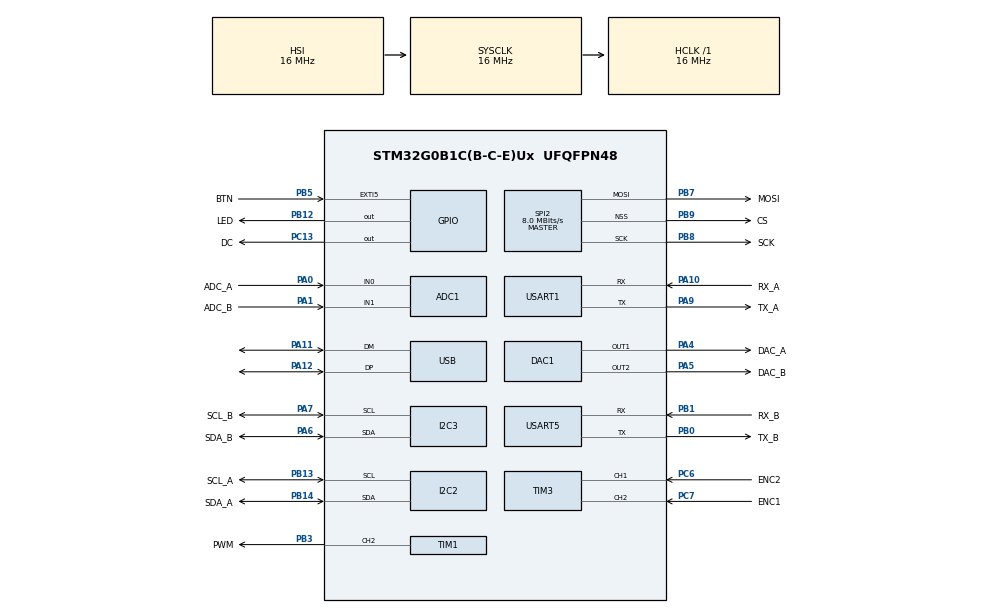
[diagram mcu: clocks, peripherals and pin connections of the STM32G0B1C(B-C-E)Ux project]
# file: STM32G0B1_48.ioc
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ADC1.ClockPrescaler=ADC_CLOCK_SYNC_PCLK_DIV2
ADC1.DMAContinuousRequests=ENABLE
ADC1.EOCSelection=ADC_EOC_SEQ_CONV
ADC1.ExternalTrigConv=ADC_EXTERNALTRIG_T6_TRGO
ADC1.NbrOfConversion=1
ADC1.NbrOfConversionFlag=0
ADC1.Overrun=ADC_OVR_DATA_PRESERVED
ADC1.OversamplingMode=ENABLE
ADC1.Ratio=ADC_OVERSAMPLING_RATIO_16
ADC1.RightBitShift=ADC_RIGHTBITSHIFT_4
ADC1.SamplingTimeCommon1=ADC_SAMPLETIME_160CYCLES_5
ADC1.SelectedChannel=ADC_CHANNEL_0|ADC_CHANNEL_1
ADC1.Sequencer=NOT_FULLY_CONFIGURABLE
ADC1.TriggerFrequencyMode=ADC_TRIGGER_FREQ_LOW
ADC1.master=1
DAC1.DAC_Channel-DAC_OUT1=DAC_CHANNEL_1
DAC1.DAC_Channel-DAC_OUT2=DAC_CHANNEL_2
Dma.ADC1.0.Direction=DMA_PERIPH_TO_MEMORY
Dma.ADC1.0.EventEnable=DISABLE
Dma.ADC1.0.Instance=DMA1_Channel1
Dma.ADC1.0.MemDataAlignment=DMA_MDATAALIGN_HALFWORD
Dma.ADC1.0.MemInc=DMA_MINC_ENABLE
Dma.ADC1.0.Mode=DMA_CIRCULAR
Dma.ADC1.0.PeriphDataAlignment=DMA_PDATAALIGN_HALFWORD
Dma.ADC1.0.PeriphInc=DMA_PINC_DISABLE
Dma.ADC1.0.Polarity=HAL_DMAMUX_REQ_GEN_RISING
Dma.ADC1.0.Priority=DMA_PRIORITY_LOW
Dma.ADC1.0.RequestNumber=1
Dma.ADC1.0.SignalID=NONE
Dma.ADC1.0.SyncEnable=DISABLE
Dma.ADC1.0.SyncPolarity=HAL_DMAMUX_SYNC_NO_EVENT
Dma.ADC1.0.SyncRequestNumber=1
Dma.ADC1.0.SyncSignalID=NONE
Dma.Request0=ADC1
I2C2.CustomTiming=Enabled
I2C2.I2C_Fall_Time=100
I2C2.I2C_Rise_Time=400
I2C2.Timing=0x306A0F13
I2C3.I2C_Fall_Time=100
I2C3.I2C_Rise_Time=400
I2C3.Timing=0x00A03D53
Mcu.Family=STM32G0
Mcu.Name=STM32G0B1C(B-C-E)Ux
Mcu.Package=UFQFPN48
Mcu.UserConstants=TIMERS_CLOCK_FREQ,16000000
NVIC.ADC1_COMP_IRQn=true\:1\:0\:true\:false\:true\:true\:true\:true
NVIC.DMA1_Channel1_IRQn=true\:0\:0\:false\:false\:true\:false\:true\:true
NVIC.EXTI4_15_IRQn=true\:0\:0\:false\:false\:true\:true\:true\:true
NVIC.TIM3_TIM4_IRQn=true\:0\:0\:false\:false\:true\:true\:true\:true
NVIC.TIM6_DAC_LPTIM1_IRQn=true\:0\:0\:false\:false\:true\:true\:true\:true
PA0.GPIO_Label=ADC_A
PA0.Mode=IN0
PA0.Signal=ADC1_IN0
PA1.GPIO_Label=ADC_B
PA1.Mode=IN1
PA1.Signal=ADC1_IN1
PA10.GPIO_Label=RX_A
PA10.Mode=Asynchronous
PA10.Signal=USART1_RX
PA11\ [PA9].Mode=Device
PA11\ [PA9].Signal=USB_DM
PA12\ [PA10].Mode=Device
PA12\ [PA10].Signal=USB_DP
PA13.GPIO_Label=SWDIO
PA13.Mode=Serial_Wire
PA13.Signal=SYS_SWDIO
PA14-BOOT0.GPIO_Label=SWCLK
PA14-BOOT0.Mode=Serial_Wire
PA14-BOOT0.Signal=SYS_SWCLK
PA4.GPIO_Label=DAC_A
PA4.Signal=COMP_DAC11_group
PA5.GPIO_Label=DAC_B
PA5.Signal=COMP_DAC12_group
PA6.GPIO_Label=SDA_B
PA6.Mode=I2C
PA6.Signal=I2C3_SDA
PA7.GPIO_Label=SCL_B
PA7.Mode=I2C
PA7.Signal=I2C3_SCL
PA9.GPIO_Label=TX_A
PA9.Mode=Asynchronous
PA9.Signal=USART1_TX
PB0.GPIO_Label=TX_B
PB0.Mode=Asynchronous
PB0.Signal=USART5_TX
PB1.GPIO_Label=RX_B
PB1.Mode=Asynchronous
PB1.Signal=USART5_RX
PB12.GPIO_Label=LED
PB12.GPIO_ModeDefaultOutputPP=GPIO_MODE_OUTPUT_PP
PB12.GPIO_PuPd=GPIO_NOPULL
PB12.Signal=GPIO_Output
PB13.GPIO_Label=SCL_A
PB13.Mode=I2C
PB13.Signal=I2C2_SCL
PB14.GPIO_Label=SDA_A
PB14.Mode=I2C
PB14.Signal=I2C2_SDA
PB3.GPIO_Label=PWM
PB3.Signal=S_TIM1_CH2
PB5.GPIO_Label=BTN
PB5.Signal=GPXTI5
PB7.GPIO_Label=MOSI
PB7.Mode=TX_Only_Simplex_Unidirect_Master
PB7.Signal=SPI2_MOSI
PB8.GPIO_Label=SCK
PB8.Mode=TX_Only_Simplex_Unidirect_Master
PB8.Signal=SPI2_SCK
PB9.GPIO_Label=CS
PB9.Mode=NSS_Signal_Hard_Output
PB9.Signal=SPI2_NSS
PC13.GPIO_Label=DC
PC13.Signal=GPIO_Output
PC6.GPIO_Label=ENC2
PC6.Signal=S_TIM3_CH1
PC7.GPIO_Label=ENC1
PC7.Signal=S_TIM3_CH2
ProjectManager.HeapSize=0x200
ProjectManager.StackSize=0x400
ProjectManager.TargetToolchain=STM32CubeIDE
RCC.ADCCLockSelection=RCC_ADCCLKSOURCE_HSI
RCC.ADCFreq_Value=16000000
RCC.AHBFreq_Value=16000000
RCC.CortexFreq_Value=16000000
RCC.EXTERNAL_CLOCK_VALUE=48000
RCC.HCLKFreq_Value=16000000
RCC.HSE_VALUE=8000000
RCC.HSI48_VALUE=48000000
RCC.HSI_VALUE=16000000
RCC.I2C2CLockSelection=RCC_I2C2CLKSOURCE_SYSCLK
RCC.LSE_VALUE=32768
RCC.SYSCLKFreq_VALUE=16000000
RCC.USBFreq_Value=48000000
RCC.VCOOutputFreq_Value=128000000
SH.COMP_DAC11_group.0=DAC1_OUT1,DAC_OUT1
SH.COMP_DAC12_group.0=DAC1_OUT2,DAC_OUT2
SH.S_TIM1_CH2.0=TIM1_CH2,PWM Generation2 CH2
SH.S_TIM3_CH1.0=TIM3_CH1,Encoder_Interface
SH.S_TIM3_CH2.0=TIM3_CH2,Encoder_Interface
SPI2.CalculateBaudRate=8.0 MBits/s
SPI2.Direction=SPI_DIRECTION_2LINES
SPI2.Mode=SPI_MODE_MASTER
SPI2.VirtualNSS=VM_NSSHARD
SPI2.VirtualType=VM_MASTER
TIM1.Channel-PWM\ Generation2\ CH2=TIM_CHANNEL_2
TIM1.Period=(TIMERS_CLOCK_FREQ/1000)-1
TIM3.IC1Filter=10
TIM3.IC2Filter=10
TIM6.Period=250-1
TIM6.Prescaler=(TIMERS_CLOCK_FREQ/1000)-1
TIM6.TIM_MasterOutputTrigger=TIM_TRGO_UPDATE
USART1.VirtualMode-Asynchronous=VM_ASYNC
USART5.VirtualMode-Asynchronous=VM_ASYNC
VP_SYS_VS_DBSignals.Mode=DisableDeadBatterySignals
VP_SYS_V_VREFBUF.Mode=ExternalMode
VP_TIM1_VS_ClockSourceINT.Mode=Internal
VP_TIM6_VS_ClockSourceINT.Mode=Enable_Timer
board=custom

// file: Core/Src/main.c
/* USER CODE BEGIN Header */
/**
  ******************************************************************************
  * @file           : main.c
  * @brief          : Main program body
  ******************************************************************************
  * @attention
  *
  * Copyright (c) 2021 STMicroelectronics.
  * All rights reserved.
  *
  * This software is licensed under terms that can be found in the LICENSE file
  * in the root directory of this software component.
  * If no LICENSE file comes with this software, it is provided AS-IS.
  *
  ******************************************************************************
  */
/* USER CODE END Header */
#include "main.h"

/* USER CODE BEGIN Includes */
#include "master.h"
/* USER CODE END Includes */

/* USER CODE BEGIN PM */
// ?
/* USER CODE END PM */

ADC_HandleTypeDef hadc1;
DMA_HandleTypeDef hdma_adc1;

DAC_HandleTypeDef hdac1;

I2C_HandleTypeDef hi2c2;
I2C_HandleTypeDef hi2c3;

SPI_HandleTypeDef hspi2;

TIM_HandleTypeDef htim1;
TIM_HandleTypeDef htim3;
TIM_HandleTypeDef htim6;

UART_HandleTypeDef huart1;
UART_HandleTypeDef huart5;

PCD_HandleTypeDef hpcd_USB_DRD_FS;

void SystemClock_Config(void);
static void MX_GPIO_Init(void);
static void MX_DMA_Init(void);
static void MX_I2C2_Init(void);
static void MX_I2C3_Init(void);
static void MX_SPI2_Init(void);
static void MX_TIM1_Init(void);
static void MX_TIM3_Init(void);
static void MX_TIM6_Init(void);
static void MX_ADC1_Init(void);
static void MX_DAC1_Init(void);
static void MX_USART1_UART_Init(void);
static void MX_USART5_UART_Init(void);
static void MX_USB_DRD_FS_PCD_Init(void);

int main(void)
{
  /* USER CODE BEGIN 1 */
 PreInit();
  /* USER CODE END 1 */

  /* MCU Configuration--------------------------------------------------------*/

  /* Reset of all peripherals, Initializes the Flash interface and the Systick. */
  HAL_Init();

  /* USER CODE BEGIN Init */
  Init();
  /* USER CODE END Init */

  /* Configure the system clock */
  SystemClock_Config();

  /* USER CODE BEGIN SysInit */
  SysInit();
  /* USER CODE END SysInit */

  /* Initialize all configured peripherals */
  MX_GPIO_Init();
  MX_DMA_Init();
  MX_I2C2_Init();
  MX_I2C3_Init();
  MX_SPI2_Init();
  MX_TIM1_Init();
  MX_TIM3_Init();
  MX_TIM6_Init();
  MX_ADC1_Init();
  MX_DAC1_Init();
  MX_USART1_UART_Init();
  MX_USART5_UART_Init();
  MX_USB_DRD_FS_PCD_Init();
  /* USER CODE BEGIN 2 */
  PostInit();
  /* USER CODE END 2 */

  /* Infinite loop */
  while (1)
  {

    /* USER CODE BEGIN 3 */
    MainLoop();
  }
  /* USER CODE END 3 */
}

void SystemClock_Config(void)
{
  RCC_OscInitTypeDef RCC_OscInitStruct = {0};
  RCC_ClkInitTypeDef RCC_ClkInitStruct = {0};

  /** Configure the main internal regulator output voltage
  */
  HAL_PWREx_ControlVoltageScaling(PWR_REGULATOR_VOLTAGE_SCALE1);
  /** Initializes the RCC Oscillators according to the specified parameters
  * in the RCC_OscInitTypeDef structure.
  */
  RCC_OscInitStruct.OscillatorType = RCC_OSCILLATORTYPE_HSI|RCC_OSCILLATORTYPE_HSI48;
  RCC_OscInitStruct.HSIState = RCC_HSI_ON;
  RCC_OscInitStruct.HSI48State = RCC_HSI48_ON;
  RCC_OscInitStruct.HSIDiv = RCC_HSI_DIV1;
  RCC_OscInitStruct.HSICalibrationValue = RCC_HSICALIBRATION_DEFAULT;
  RCC_OscInitStruct.PLL.PLLState = RCC_PLL_NONE;
  if (HAL_RCC_OscConfig(&RCC_OscInitStruct) != HAL_OK)
  {
    Error_Handler();
  }
  /** Initializes the CPU, AHB and APB buses clocks
  */
  RCC_ClkInitStruct.ClockType = RCC_CLOCKTYPE_HCLK|RCC_CLOCKTYPE_SYSCLK
                              |RCC_CLOCKTYPE_PCLK1;
  RCC_ClkInitStruct.SYSCLKSource = RCC_SYSCLKSOURCE_HSI;
  RCC_ClkInitStruct.AHBCLKDivider = RCC_SYSCLK_DIV1;
  RCC_ClkInitStruct.APB1CLKDivider = RCC_HCLK_DIV1;

  if (HAL_RCC_ClockConfig(&RCC_ClkInitStruct, FLASH_LATENCY_0) != HAL_OK)
  {
    Error_Handler();
  }
}

static void MX_ADC1_Init(void)
{

  ADC_ChannelConfTypeDef sConfig = {0};

  /** Configure the global features of the ADC (Clock, Resolution, Data Alignment and number of conversion)
  */
  hadc1.Instance = ADC1;
  hadc1.Init.ClockPrescaler = ADC_CLOCK_SYNC_PCLK_DIV2;
  hadc1.Init.Resolution = ADC_RESOLUTION_12B;
  hadc1.Init.DataAlign = ADC_DATAALIGN_RIGHT;
  hadc1.Init.ScanConvMode = ADC_SCAN_SEQ_FIXED;
  hadc1.Init.EOCSelection = ADC_EOC_SEQ_CONV;
  hadc1.Init.LowPowerAutoWait = DISABLE;
  hadc1.Init.LowPowerAutoPowerOff = DISABLE;
  hadc1.Init.ContinuousConvMode = DISABLE;
  hadc1.Init.NbrOfConversion = 1;
  hadc1.Init.DiscontinuousConvMode = DISABLE;
  hadc1.Init.ExternalTrigConv = ADC_EXTERNALTRIG_T6_TRGO;
  hadc1.Init.ExternalTrigConvEdge = ADC_EXTERNALTRIGCONVEDGE_RISING;
  hadc1.Init.DMAContinuousRequests = ENABLE;
  hadc1.Init.Overrun = ADC_OVR_DATA_PRESERVED;
  hadc1.Init.SamplingTimeCommon1 = ADC_SAMPLETIME_160CYCLES_5;
  hadc1.Init.OversamplingMode = ENABLE;
  hadc1.Init.Oversampling.Ratio = ADC_OVERSAMPLING_RATIO_16;
  hadc1.Init.Oversampling.RightBitShift = ADC_RIGHTBITSHIFT_4;
  hadc1.Init.Oversampling.TriggeredMode = ADC_TRIGGEREDMODE_SINGLE_TRIGGER;
  hadc1.Init.TriggerFrequencyMode = ADC_TRIGGER_FREQ_LOW;
  if (HAL_ADC_Init(&hadc1) != HAL_OK)
  {
    Error_Handler();
  }
  /** Configure Regular Channel
  */
  sConfig.Channel = ADC_CHANNEL_0;
  sConfig.Rank = ADC_RANK_CHANNEL_NUMBER;
  if (HAL_ADC_ConfigChannel(&hadc1, &sConfig) != HAL_OK)
  {
    Error_Handler();
  }
  /** Configure Regular Channel
  */
  sConfig.Channel = ADC_CHANNEL_1;
  if (HAL_ADC_ConfigChannel(&hadc1, &sConfig) != HAL_OK)
  {
    Error_Handler();
  }

}

static void MX_DAC1_Init(void)
{

  DAC_ChannelConfTypeDef sConfig = {0};

  /** DAC Initialization
  */
  hdac1.Instance = DAC1;
  if (HAL_DAC_Init(&hdac1) != HAL_OK)
  {
    Error_Handler();
  }
  /** DAC channel OUT1 config
  */
  sConfig.DAC_SampleAndHold = DAC_SAMPLEANDHOLD_DISABLE;
  sConfig.DAC_Trigger = DAC_TRIGGER_NONE;
  sConfig.DAC_OutputBuffer = DAC_OUTPUTBUFFER_ENABLE;
  sConfig.DAC_ConnectOnChipPeripheral = DAC_CHIPCONNECT_DISABLE;
  sConfig.DAC_UserTrimming = DAC_TRIMMING_FACTORY;
  if (HAL_DAC_ConfigChannel(&hdac1, &sConfig, DAC_CHANNEL_1) != HAL_OK)
  {
    Error_Handler();
  }
  /** DAC channel OUT2 config
  */
  if (HAL_DAC_ConfigChannel(&hdac1, &sConfig, DAC_CHANNEL_2) != HAL_OK)
  {
    Error_Handler();
  }

}

static void MX_I2C2_Init(void)
{

  hi2c2.Instance = I2C2;
  hi2c2.Init.Timing = 0x306A0F13;
  hi2c2.Init.OwnAddress1 = 0;
  hi2c2.Init.AddressingMode = I2C_ADDRESSINGMODE_7BIT;
  hi2c2.Init.DualAddressMode = I2C_DUALADDRESS_DISABLE;
  hi2c2.Init.OwnAddress2 = 0;
  hi2c2.Init.OwnAddress2Masks = I2C_OA2_NOMASK;
  hi2c2.Init.GeneralCallMode = I2C_GENERALCALL_DISABLE;
  hi2c2.Init.NoStretchMode = I2C_NOSTRETCH_DISABLE;
  if (HAL_I2C_Init(&hi2c2) != HAL_OK)
  {
    Error_Handler();
  }
  /** Configure Analogue filter
  */
  if (HAL_I2CEx_ConfigAnalogFilter(&hi2c2, I2C_ANALOGFILTER_ENABLE) != HAL_OK)
  {
    Error_Handler();
  }
  /** Configure Digital filter
  */
  if (HAL_I2CEx_ConfigDigitalFilter(&hi2c2, 0) != HAL_OK)
  {
    Error_Handler();
  }

}

static void MX_I2C3_Init(void)
{

  hi2c3.Instance = I2C3;
  hi2c3.Init.Timing = 0x00A03D53;
  hi2c3.Init.OwnAddress1 = 0;
  hi2c3.Init.AddressingMode = I2C_ADDRESSINGMODE_7BIT;
  hi2c3.Init.DualAddressMode = I2C_DUALADDRESS_DISABLE;
  hi2c3.Init.OwnAddress2 = 0;
  hi2c3.Init.OwnAddress2Masks = I2C_OA2_NOMASK;
  hi2c3.Init.GeneralCallMode = I2C_GENERALCALL_DISABLE;
  hi2c3.Init.NoStretchMode = I2C_NOSTRETCH_DISABLE;
  if (HAL_I2C_Init(&hi2c3) != HAL_OK)
  {
    Error_Handler();
  }
  /** Configure Analogue filter
  */
  if (HAL_I2CEx_ConfigAnalogFilter(&hi2c3, I2C_ANALOGFILTER_ENABLE) != HAL_OK)
  {
    Error_Handler();
  }
  /** Configure Digital filter
  */
  if (HAL_I2CEx_ConfigDigitalFilter(&hi2c3, 0) != HAL_OK)
  {
    Error_Handler();
  }

}

static void MX_SPI2_Init(void)
{

  /* SPI2 parameter configuration*/
  hspi2.Instance = SPI2;
  hspi2.Init.Mode = SPI_MODE_MASTER;
  hspi2.Init.Direction = SPI_DIRECTION_2LINES;
  hspi2.Init.DataSize = SPI_DATASIZE_8BIT;
  hspi2.Init.CLKPolarity = SPI_POLARITY_LOW;
  hspi2.Init.CLKPhase = SPI_PHASE_1EDGE;
  hspi2.Init.NSS = SPI_NSS_HARD_OUTPUT;
  hspi2.Init.BaudRatePrescaler = SPI_BAUDRATEPRESCALER_2;
  hspi2.Init.FirstBit = SPI_FIRSTBIT_MSB;
  hspi2.Init.TIMode = SPI_TIMODE_DISABLE;
  hspi2.Init.CRCCalculation = SPI_CRCCALCULATION_DISABLE;
  hspi2.Init.CRCPolynomial = 7;
  hspi2.Init.CRCLength = SPI_CRC_LENGTH_DATASIZE;
  hspi2.Init.NSSPMode = SPI_NSS_PULSE_ENABLE;
  if (HAL_SPI_Init(&hspi2) != HAL_OK)
  {
    Error_Handler();
  }

}

static void MX_TIM1_Init(void)
{

  TIM_ClockConfigTypeDef sClockSourceConfig = {0};
  TIM_MasterConfigTypeDef sMasterConfig = {0};
  TIM_OC_InitTypeDef sConfigOC = {0};
  TIM_BreakDeadTimeConfigTypeDef sBreakDeadTimeConfig = {0};

  htim1.Instance = TIM1;
  htim1.Init.Prescaler = 0;
  htim1.Init.CounterMode = TIM_COUNTERMODE_UP;
  htim1.Init.Period = (TIMERS_CLOCK_FREQ/1000)-1;
  htim1.Init.ClockDivision = TIM_CLOCKDIVISION_DIV1;
  htim1.Init.RepetitionCounter = 0;
  htim1.Init.AutoReloadPreload = TIM_AUTORELOAD_PRELOAD_DISABLE;
  if (HAL_TIM_Base_Init(&htim1) != HAL_OK)
  {
    Error_Handler();
  }
  sClockSourceConfig.ClockSource = TIM_CLOCKSOURCE_INTERNAL;
  if (HAL_TIM_ConfigClockSource(&htim1, &sClockSourceConfig) != HAL_OK)
  {
    Error_Handler();
  }
  if (HAL_TIM_PWM_Init(&htim1) != HAL_OK)
  {
    Error_Handler();
  }
  sMasterConfig.MasterOutputTrigger = TIM_TRGO_RESET;
  sMasterConfig.MasterOutputTrigger2 = TIM_TRGO2_RESET;
  sMasterConfig.MasterSlaveMode = TIM_MASTERSLAVEMODE_DISABLE;
  if (HAL_TIMEx_MasterConfigSynchronization(&htim1, &sMasterConfig) != HAL_OK)
  {
    Error_Handler();
  }
  sConfigOC.OCMode = TIM_OCMODE_PWM1;
  sConfigOC.Pulse = 0;
  sConfigOC.OCPolarity = TIM_OCPOLARITY_HIGH;
  sConfigOC.OCNPolarity = TIM_OCNPOLARITY_HIGH;
  sConfigOC.OCFastMode = TIM_OCFAST_DISABLE;
  sConfigOC.OCIdleState = TIM_OCIDLESTATE_RESET;
  sConfigOC.OCNIdleState = TIM_OCNIDLESTATE_RESET;
  if (HAL_TIM_PWM_ConfigChannel(&htim1, &sConfigOC, TIM_CHANNEL_2) != HAL_OK)
  {
    Error_Handler();
  }
  sBreakDeadTimeConfig.OffStateRunMode = TIM_OSSR_DISABLE;
  sBreakDeadTimeConfig.OffStateIDLEMode = TIM_OSSI_DISABLE;
  sBreakDeadTimeConfig.LockLevel = TIM_LOCKLEVEL_OFF;
  sBreakDeadTimeConfig.DeadTime = 0;
  sBreakDeadTimeConfig.BreakState = TIM_BREAK_DISABLE;
  sBreakDeadTimeConfig.BreakPolarity = TIM_BREAKPOLARITY_HIGH;
  sBreakDeadTimeConfig.BreakFilter = 0;
  sBreakDeadTimeConfig.BreakAFMode = TIM_BREAK_AFMODE_INPUT;
  sBreakDeadTimeConfig.Break2State = TIM_BREAK2_DISABLE;
  sBreakDeadTimeConfig.Break2Polarity = TIM_BREAK2POLARITY_HIGH;
  sBreakDeadTimeConfig.Break2Filter = 0;
  sBreakDeadTimeConfig.Break2AFMode = TIM_BREAK_AFMODE_INPUT;
  sBreakDeadTimeConfig.AutomaticOutput = TIM_AUTOMATICOUTPUT_DISABLE;
  if (HAL_TIMEx_ConfigBreakDeadTime(&htim1, &sBreakDeadTimeConfig) != HAL_OK)
  {
    Error_Handler();
  }
  HAL_TIM_MspPostInit(&htim1);

}

static void MX_TIM3_Init(void)
{

  TIM_Encoder_InitTypeDef sConfig = {0};
  TIM_MasterConfigTypeDef sMasterConfig = {0};

  htim3.Instance = TIM3;
  htim3.Init.Prescaler = 0;
  htim3.Init.CounterMode = TIM_COUNTERMODE_UP;
  htim3.Init.Period = 65535;
  htim3.Init.ClockDivision = TIM_CLOCKDIVISION_DIV1;
  htim3.Init.AutoReloadPreload = TIM_AUTORELOAD_PRELOAD_DISABLE;
  sConfig.EncoderMode = TIM_ENCODERMODE_TI1;
  sConfig.IC1Polarity = TIM_ICPOLARITY_RISING;
  sConfig.IC1Selection = TIM_ICSELECTION_DIRECTTI;
  sConfig.IC1Prescaler = TIM_ICPSC_DIV1;
  sConfig.IC1Filter = 10;
  sConfig.IC2Polarity = TIM_ICPOLARITY_RISING;
  sConfig.IC2Selection = TIM_ICSELECTION_DIRECTTI;
  sConfig.IC2Prescaler = TIM_ICPSC_DIV1;
  sConfig.IC2Filter = 10;
  if (HAL_TIM_Encoder_Init(&htim3, &sConfig) != HAL_OK)
  {
    Error_Handler();
  }
  sMasterConfig.MasterOutputTrigger = TIM_TRGO_RESET;
  sMasterConfig.MasterSlaveMode = TIM_MASTERSLAVEMODE_DISABLE;
  if (HAL_TIMEx_MasterConfigSynchronization(&htim3, &sMasterConfig) != HAL_OK)
  {
    Error_Handler();
  }

}

static void MX_TIM6_Init(void)
{

  TIM_MasterConfigTypeDef sMasterConfig = {0};

  htim6.Instance = TIM6;
  htim6.Init.Prescaler = (TIMERS_CLOCK_FREQ/1000)-1;
  htim6.Init.CounterMode = TIM_COUNTERMODE_UP;
  htim6.Init.Period = 250-1;
  htim6.Init.AutoReloadPreload = TIM_AUTORELOAD_PRELOAD_DISABLE;
  if (HAL_TIM_Base_Init(&htim6) != HAL_OK)
  {
    Error_Handler();
  }
  sMasterConfig.MasterOutputTrigger = TIM_TRGO_UPDATE;
  sMasterConfig.MasterSlaveMode = TIM_MASTERSLAVEMODE_DISABLE;
  if (HAL_TIMEx_MasterConfigSynchronization(&htim6, &sMasterConfig) != HAL_OK)
  {
    Error_Handler();
  }

}

static void MX_USART1_UART_Init(void)
{

  huart1.Instance = USART1;
  huart1.Init.BaudRate = 115200;
  huart1.Init.WordLength = UART_WORDLENGTH_8B;
  huart1.Init.StopBits = UART_STOPBITS_1;
  huart1.Init.Parity = UART_PARITY_NONE;
  huart1.Init.Mode = UART_MODE_TX_RX;
  huart1.Init.HwFlowCtl = UART_HWCONTROL_NONE;
  huart1.Init.OverSampling = UART_OVERSAMPLING_16;
  huart1.Init.OneBitSampling = UART_ONE_BIT_SAMPLE_DISABLE;
  huart1.Init.ClockPrescaler = UART_PRESCALER_DIV1;
  huart1.AdvancedInit.AdvFeatureInit = UART_ADVFEATURE_NO_INIT;
  if (HAL_UART_Init(&huart1) != HAL_OK)
  {
    Error_Handler();
  }
  if (HAL_UARTEx_SetTxFifoThreshold(&huart1, UART_TXFIFO_THRESHOLD_1_8) != HAL_OK)
  {
    Error_Handler();
  }
  if (HAL_UARTEx_SetRxFifoThreshold(&huart1, UART_RXFIFO_THRESHOLD_1_8) != HAL_OK)
  {
    Error_Handler();
  }
  if (HAL_UARTEx_DisableFifoMode(&huart1) != HAL_OK)
  {
    Error_Handler();
  }

}

static void MX_USART5_UART_Init(void)
{

  huart5.Instance = USART5;
  huart5.Init.BaudRate = 115200;
  huart5.Init.WordLength = UART_WORDLENGTH_8B;
  huart5.Init.StopBits = UART_STOPBITS_1;
  huart5.Init.Parity = UART_PARITY_NONE;
  huart5.Init.Mode = UART_MODE_TX_RX;
  huart5.Init.HwFlowCtl = UART_HWCONTROL_NONE;
  huart5.Init.OverSampling = UART_OVERSAMPLING_16;
  huart5.Init.OneBitSampling = UART_ONE_BIT_SAMPLE_DISABLE;
  huart5.Init.ClockPrescaler = UART_PRESCALER_DIV1;
  huart5.AdvancedInit.AdvFeatureInit = UART_ADVFEATURE_NO_INIT;
  if (HAL_UART_Init(&huart5) != HAL_OK)
  {
    Error_Handler();
  }

}

static void MX_USB_DRD_FS_PCD_Init(void)
{

  hpcd_USB_DRD_FS.Instance = USB_DRD_FS;
  hpcd_USB_DRD_FS.Init.dev_endpoints = 8;
  hpcd_USB_DRD_FS.Init.Host_channels = 8;
  hpcd_USB_DRD_FS.Init.speed = USBD_FS_SPEED;
  hpcd_USB_DRD_FS.Init.phy_itface = PCD_PHY_EMBEDDED;
  hpcd_USB_DRD_FS.Init.Sof_enable = DISABLE;
  hpcd_USB_DRD_FS.Init.low_power_enable = DISABLE;
  hpcd_USB_DRD_FS.Init.lpm_enable = DISABLE;
  hpcd_USB_DRD_FS.Init.battery_charging_enable = DISABLE;
  hpcd_USB_DRD_FS.Init.vbus_sensing_enable = DISABLE;
  hpcd_USB_DRD_FS.Init.bulk_doublebuffer_enable = DISABLE;
  hpcd_USB_DRD_FS.Init.iso_singlebuffer_enable = DISABLE;
  if (HAL_PCD_Init(&hpcd_USB_DRD_FS) != HAL_OK)
  {
    Error_Handler();
  }

}

static void MX_DMA_Init(void)
{

  /* DMA controller clock enable */
  __HAL_RCC_DMA1_CLK_ENABLE();

  /* DMA interrupt init */
  /* DMA1_Channel1_IRQn interrupt configuration */
  HAL_NVIC_SetPriority(DMA1_Channel1_IRQn, 0, 0);
  HAL_NVIC_EnableIRQ(DMA1_Channel1_IRQn);

}

static void MX_GPIO_Init(void)
{
  GPIO_InitTypeDef GPIO_InitStruct = {0};

  /* GPIO Ports Clock Enable */
  __HAL_RCC_GPIOC_CLK_ENABLE();
  __HAL_RCC_GPIOA_CLK_ENABLE();
  __HAL_RCC_GPIOB_CLK_ENABLE();

  /*Configure GPIO pin Output Level */
  HAL_GPIO_WritePin(DC_GPIO_Port, DC_Pin, GPIO_PIN_RESET);

  /*Configure GPIO pin Output Level */
  HAL_GPIO_WritePin(LED_GPIO_Port, LED_Pin, GPIO_PIN_RESET);

  /*Configure GPIO pin : DC_Pin */
  GPIO_InitStruct.Pin = DC_Pin;
  GPIO_InitStruct.Mode = GPIO_MODE_OUTPUT_PP;
  GPIO_InitStruct.Pull = GPIO_NOPULL;
  GPIO_InitStruct.Speed = GPIO_SPEED_FREQ_LOW;
  HAL_GPIO_Init(DC_GPIO_Port, &GPIO_InitStruct);

  /*Configure GPIO pin : LED_Pin */
  GPIO_InitStruct.Pin = LED_Pin;
  GPIO_InitStruct.Mode = GPIO_MODE_OUTPUT_PP;
  GPIO_InitStruct.Pull = GPIO_NOPULL;
  GPIO_InitStruct.Speed = GPIO_SPEED_FREQ_LOW;
  HAL_GPIO_Init(LED_GPIO_Port, &GPIO_InitStruct);

  /*Configure GPIO pin : BTN_Pin */
  GPIO_InitStruct.Pin = BTN_Pin;
  GPIO_InitStruct.Mode = GPIO_MODE_IT_RISING;
  GPIO_InitStruct.Pull = GPIO_NOPULL;
  HAL_GPIO_Init(BTN_GPIO_Port, &GPIO_InitStruct);

  /* EXTI interrupt init*/
  HAL_NVIC_SetPriority(EXTI4_15_IRQn, 0, 0);
  HAL_NVIC_EnableIRQ(EXTI4_15_IRQn);

}

void Error_Handler(void)
{
  __disable_irq();
  while (1)
  {
  }
}
